# LKS32MC07x register map
Vendor: Linko Ltd.; Series: LKS32MC07x; File version: 1.0
CPU: CM0 r1p0, little endian, MPU, no FPU, 3 interrupt priority bits
Registers are 32-bit, read-write, reset 0x0 unless marked. A register's access mark holds for its fields unless they carry their own. Offsets are from the block's base; [hi:lo] are bit positions; {n}, {i} and the like mark numbered series; 'fields as' and 'values as' point back to an identical list.

## TIMER3 — TIMER3 registers
Base 0x40010900
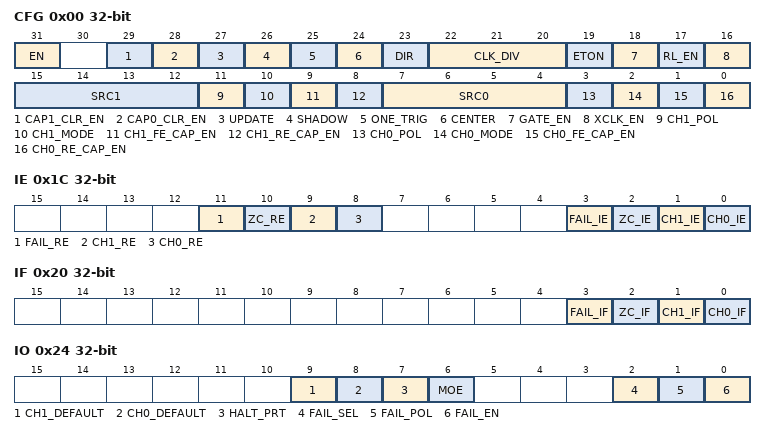
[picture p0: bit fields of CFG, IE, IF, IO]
0x00 CFG — Timer configuration
  [31] EN — Timer Enable
  [29] CAP1_CLR_EN — Timer Counter Clear when CAP1 event happens
  [28] CAP0_CLR_EN — Timer Counter Clear when CAP1 event happens
  [27] UPDATE — Software update
  [26] SHADOW — Shadow Register Enable
  [25] ONE_TRIG — One Trig Send Mode Enable
  [24] CENTER — Center Counter Mode Enable
  [23] DIR — Counter Direction
  [22:20] CLK_DIV — Timer clock division ratio
    0=DIV1; 1=DIV2; 2=DIV4; 3=DIV8; 4=DIV16; 5=DIV32; 6=DIV64; 7=DIV128
  [19] ETON — Timer external trigger
    0=IT (Free run); 1=ET (Extrenal trigger)
  [18] GATE_EN — Timer Stop Enable
  [17] RL_EN — Timer Reload Enable
  [16] XCLK_EN — Timer Clock Source
  [15:12] SRC1 — Channel 1 data source
    0=CH0 (Use timer3 channel 0 as capture source); 1=CH1 (Use timer3 channel 1 as capture source); {v}=CLU{v-2}OUT (Use clu{v-2} output as capture source) (v=2..5); 6=CMP0OUT (Use cmp0 output as capture source); 7=CMP1OUT (Use cmp1 output as capture source); 8=CMP2OUT (Use cmp2 output as capture source); 9=CH0XORCH1 (Use channel 0 xor channel 1 as capture source)
  [11] CH1_POL — Channel 1 output polarity at zero-crossing in comparision mode
    0=L (Output 0); 1=H (Output 1)
  [10] CH1_MODE — Channel 1 mode
    0=CMP (Comparison mode); 1=CAP (Capture mode)
  [9] CH1_FE_CAP_EN — Channel 1 falling edge capture enable
    0=Disabled (Falling edge event disabled); 1=Enabled (Falling edge event enabled)
  [8] CH1_RE_CAP_EN — Channel 1 rising edge capture enable
    0=Disabled (Rising edge event disabled); 1=Enabled (Rising edge event enabled)
  [7:4] SRC0 — Channel 0 data source
    values as SRC1
  [3] CH0_POL — Channel 0 output polarity at zero-crossing in comparision mode
    0=L (Output 0); 1=H (Output 1)
  [2] CH0_MODE — Channel 0 mode
    0=CMP (Comparison mode); 1=CAP (Capture mode)
  [1] CH0_FE_CAP_EN — Channel 0 falling edge capture enable
    0=DISABLED (Falling edge event disabled); 1=ENABLED (Falling edge event enabled)
  [0] CH0_RE_CAP_EN — Channel 0 rising edge capture enable
    0=DISABLED (Rising edge event disabled); 1=ENABLED (Rising edge event enabled)
0x04 TH — Timer counter threshold, timer will count from 0 to TH, then over again
  [31:0] TH — Counter threshold
0x08 CNT — Timer current counter value (write to set)
  [31:0] CNT — Current counter
0x0C CMP0 — Timer Channel0 CMP/CAP threshold
  [31:0] CMP0 — Timer Channel0 CMP/CAP value
0x10 CMP1 — Timer Channel1 CMP/CAP threshold
  [31:0] CMP1 — Timer Channel1 CMP/CAP value
0x14 EVT — Timer External Trigger Event
  [3:0] EVT_SRC — external event select
    0=T0_CH0 (Use timer0 channel 0 as trigger); 1=T0_CH1 (Use timer0 channel 1 as trigger); 2=T1_CH0 (Use timer1 channel 0 as trigger); 3=T1_CH1 (Use timer1 channel 1 as trigger); 4=T2_CH0 (Use timer2 channel 0 as trigger); 5=T2_CH1 (Use timer2 channel 1 as trigger); 7=T3_CH1 (Use timer3 channel 0 as trigger); 6=T3_CH0 (Use timer3 channel 1 as trigger); {v}=CLU{v-8}_RE (CLU{v-8} output Rising Edge) (v=8..11); {v}=MCPWM_TADC{v-12} (Use MCPWM TADC{v-12} as trigger) (v=12..15)
0x18 FLT — Timer Filter Control Register
  [7:0] FLT — Timer Filter Width Selection
0x1C IE — Timer Interrupt Enable
  [11] FAIL_RE — Timer FAIL Event DMA request enable
  [10] ZC_RE — Timer Counter Zero-Crossing Event DMA request enable
  [9] CH1_RE — Timer channel 1 Cmpare/Capture DMA request enable
  [8] CH0_RE — Timer channel 0 Cmpare/Capture DMA request enable
  [3] FAIL_IE — Timer FAIL event interrupt enable
  [2] ZC_IE — Timer Counter Zero-Crossing Event interrupt enable
  [1] CH1_IE — Timer channel 1 Cmpare/Capture interrupt enable
  [0] CH0_IE — Timer channel 0 Cmpare/Capture interrupt enable
0x20 IF — Timer Interrupt Flag
  [3] FAIL_IF — Timer FAIL event Flag
  [2] ZC_IF — Timer Counter Zero-Crossing Event Flag
  [1] CH1_IF — Timer channel 1 Cmpare/Capture Flag
  [0] CH0_IF — Timer channel 0 Cmpare/Capture Flag
0x24 IO — Timer IO Control Register
  [9] CH1_DEFAULT — CH1 output after Fail Event MOE clear
  [8] CH0_DEFAULT — CH1 output after Fail Event MOE clear
  [7] HALT_PRT — Timer output when CPU HALT
  [6] MOE — Timer Output when CFG.CENTER = 1
  [2] FAIL_SEL — FAIL Signal Select
  [1] FAIL_POL — FAIL Signal Polarity
  [0] FAIL_EN — FAIL Signal Enable
